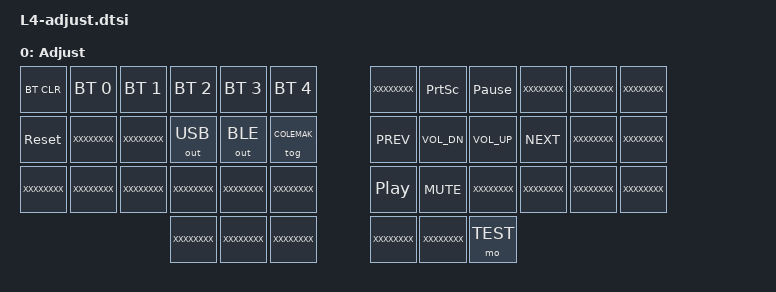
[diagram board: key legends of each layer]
/**
 *
 */

/ {
  keymap {
    compatible = "zmk,keymap";

	adjust_layer {
		label = "Adjust";
		bindings = <
// ╭───────────────┬───────────────┬───────────────┬───────────────┬───────────────┬───────────────╮   ╭───────────────┬───────────────┬───────────────┬───────────────┬───────────────┬───────────────╮
//  0               1               2               3               4               5                   6               7               8               9               10              11
	&bt BT_CLR      &bt BT_SEL 0    &bt BT_SEL 1    &bt BT_SEL 2    &bt BT_SEL 3    &bt BT_SEL 4     	XXXXXXXX   		&kp PSCRN       &kp PAUSE_BREAK XXXXXXXX        XXXXXXXX        XXXXXXXX
// ├───────────────├───────────────┼───────────────┼───────────────┼───────────────┼───────────────┤   ├───────────────├───────────────┼───────────────┼───────────────┼───────────────┼───────────────┤
//  12              13              14              15              16              17                  18              19              20              21              22              23
	&sys_reset     	XXXXXXXX		XXXXXXXX        &out OUT_USB   	&out OUT_BLE    &tog COLEMAK        &kp C_PREV      &kp C_VOL_DN    &kp C_VOL_UP    &kp C_NEXT      XXXXXXXX        XXXXXXXX
// ├───────────────├───────────────┼───────────────┼───────────────┼───────────────┼───────────────┤   ├───────────────├───────────────┼───────────────┼───────────────┼───────────────┼───────────────┤
//  24              25              26              27              28              29                  30              31              32              33              34              35
	XXXXXXXX      	XXXXXXXX		XXXXXXXX        XXXXXXXX		XXXXXXXX        XXXXXXXX            &kp C_PP        &kp C_MUTE     	XXXXXXXX        XXXXXXXX        XXXXXXXX        XXXXXXXX
// ╰───────────────┴───────────────┴───────────────┼───────────────┼───────────────┼───────────────┤   ├───────────────├───────────────┼───────────────┼───────────────┴───────────────┴───────────────╯
//                                                  36              37              38                  39              40              41
                                    	            XXXXXXXX       	XXXXXXXX        XXXXXXXX           	XXXXXXXX        XXXXXXXX        &mo TEST
//                                                 ╰───────────────┴───────────────┴───────────────╯   ╰───────────────┴───────────────┴───────────────╯
			>;
		};

  };
};
